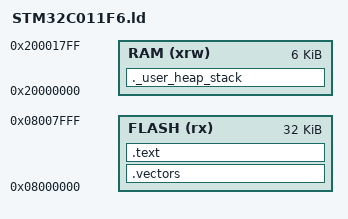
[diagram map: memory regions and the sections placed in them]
ENTRY(reset)

_Min_Heap_Size = 0x200 ; /* required amount of heap */
_Min_Stack_Size = 0x400 ; /* required amount of stack */

MEMORY
{
  FLASH (rx) : ORIGIN = 0x08000000, LENGTH = 32K
  RAM (xrw)  : ORIGIN = 0x20000000, LENGTH = 6K
}

SECTIONS
{
  .vectors :
  {
    KEEP(*(__VECTORS*))
  } > FLASH

  .text : ALIGN(16) {
    _stext = .;
    *(.text*)
    _etext = .;
  } > FLASH

  /* User_heap_stack section, used to check that there is enough "RAM" Ram  type memory left */
  ._user_heap_stack :
  {
    . = ALIGN(8);
    PROVIDE ( end = . );
    PROVIDE ( _end = . );
    . = . + _Min_Heap_Size;
    . = . + _Min_Stack_Size;
    . = ALIGN(8);
  } >RAM
}
